# NAVSS0_VIRTSS_ECC_AGGR_0_VIRTSS_ECCAGGR_CFG register map
Vendor: Texas Instruments
Peripheral module from a debugger description file (folder J721S2).
Registers are 32-bit, access not given, reset 0x0 unless marked. A register's access mark holds for its fields unless they carry their own. Offsets are as the file gives them; lines under a group give offsets from that group; [hi:lo] are bit positions; {n}, {i} and the like mark numbered series; 'fields as' and 'values as' point back to an identical list; <NAME> marks a mode.

## NAVSS0_VIRTSS_ECC_AGGR_0_VIRTSS_ECCAGGR_CFG
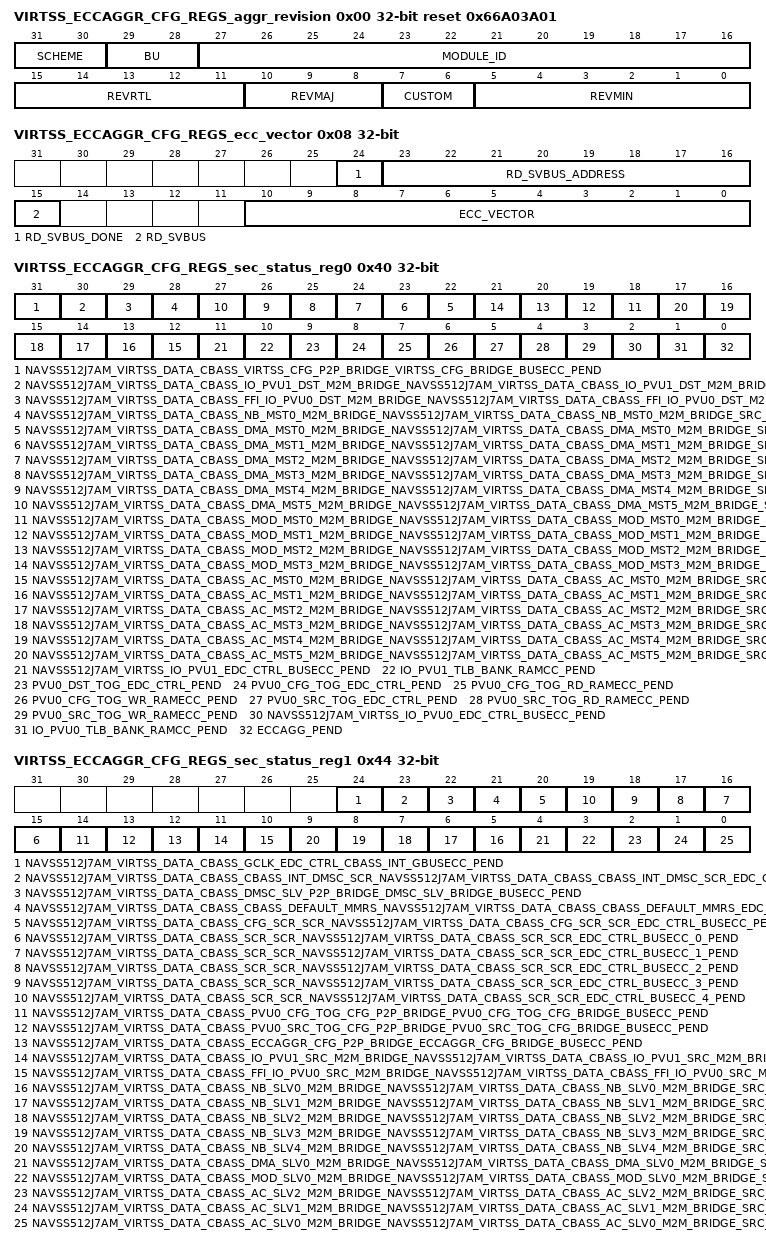
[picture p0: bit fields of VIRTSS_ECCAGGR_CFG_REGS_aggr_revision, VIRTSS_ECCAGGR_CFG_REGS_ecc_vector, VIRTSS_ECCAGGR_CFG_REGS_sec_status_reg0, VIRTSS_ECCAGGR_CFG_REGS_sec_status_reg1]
0x00 VIRTSS_ECCAGGR_CFG_REGS_aggr_revision ro reset 0x66A03A01 — Revision parameters
  [31:30] SCHEME
  [29:28] BU
  [27:16] MODULE_ID
  [15:11] REVRTL — RTL version
  [10:8] REVMAJ — Major version
  [7:6] CUSTOM — Custom version
  [5:0] REVMIN — Minor version
0x08 VIRTSS_ECCAGGR_CFG_REGS_ecc_vector — ECC Vector Register
  [24] RD_SVBUS_DONE — Status to indicate if read on serial VBUS is complete, write of any value will clear this bit. (access R/W1TC)
  [23:16] RD_SVBUS_ADDRESS rw — Read address
  [15] RD_SVBUS — Write 1 to trigger a read on the serial VBUS (access R/W1TS)
  [10:0] ECC_VECTOR rw — Value written to select the corresponding ECC RAM for control or status
0x0C VIRTSS_ECCAGGR_CFG_REGS_misc_status ro reset 0x39 — Misc Status
  [10:0] NUM_RAMS — Indicates the number of RAMS serviced by the ECC aggregator
0x10 VIRTSS_ECCAGGR_CFG_REGS_reserved_svbus rw — Reference other documents that contain the ECC RAM wrapper and EDC controller serial vbus register sets.
  [31:0] DATA — Serial VBUS register data
0x3C VIRTSS_ECCAGGR_CFG_REGS_sec_eoi_reg — EOI Register
  [0] EOI_WR — EOI Register (access R/W1TS)
0x40 VIRTSS_ECCAGGR_CFG_REGS_sec_status_reg0 — Interrupt Status Register 0
  [31] NAVSS512J7AM_VIRTSS_DATA_CBASS_VIRTSS_CFG_P2P_BRIDGE_VIRTSS_CFG_BRIDGE_BUSECC_PEND — Interrupt Pending Status for navss512j7am_virtss_data_cbass_virtss_cfg_p2p_bridge_virtss_cfg_bridge_busecc_pend (access R/W1TS)
  [30] NAVSS512J7AM_VIRTSS_DATA_CBASS_IO_PVU1_DST_M2M_BRIDGE_NAVSS512J7AM_VIRTSS_DATA_CBASS_IO_PVU1_DST_M2M_BRIDGE_SRC_EDC_CTRL_BUSECC_PEND — Interrupt Pending Status for navss512j7am_virtss_data_cbass_io_pvu1_dst_m2m_bridge_navss512j7am_virtss_data_cbass_io_pvu1_dst_m2m_bridge_src_edc_ctrl_busecc_pend (access R/W1TS)
  [29] NAVSS512J7AM_VIRTSS_DATA_CBASS_FFI_IO_PVU0_DST_M2M_BRIDGE_NAVSS512J7AM_VIRTSS_DATA_CBASS_FFI_IO_PVU0_DST_M2M_BRIDGE_SRC_EDC_CTRL_BUSECC_PEND — Interrupt Pending Status for navss512j7am_virtss_data_cbass_ffi_io_pvu0_dst_m2m_bridge_navss512j7am_virtss_data_cbass_ffi_io_pvu0_dst_m2m_bridge_src_edc_ctrl_busecc_pend (access R/W1TS)
  [28] NAVSS512J7AM_VIRTSS_DATA_CBASS_NB_MST0_M2M_BRIDGE_NAVSS512J7AM_VIRTSS_DATA_CBASS_NB_MST0_M2M_BRIDGE_SRC_EDC_CTRL_BUSECC_PEND — Interrupt Pending Status for navss512j7am_virtss_data_cbass_nb_mst0_m2m_bridge_navss512j7am_virtss_data_cbass_nb_mst0_m2m_bridge_src_edc_ctrl_busecc_pend (access R/W1TS)
  [n+22] NAVSS512J7AM_VIRTSS_DATA_CBASS_DMA_MST{n}_M2M_BRIDGE_NAVSS512J7AM_VIRTSS_DATA_CBASS_DMA_MST{n}_M2M_BRIDGE_SRC_EDC_CTRL_BUSECC_PEND (n=0..5) — Interrupt Pending Status for navss512j7am_virtss_data_cbass_dma_mst{n}_m2m_bridge_navss512j7am_virtss_data_cbass_dma_mst{n}_m2m_bridge_src_edc_ctrl_busecc_pend (access R/W1TS)
  [n+18] NAVSS512J7AM_VIRTSS_DATA_CBASS_MOD_MST{n}_M2M_BRIDGE_NAVSS512J7AM_VIRTSS_DATA_CBASS_MOD_MST{n}_M2M_BRIDGE_SRC_EDC_CTRL_BUSECC_PEND (n=0..3) — Interrupt Pending Status for navss512j7am_virtss_data_cbass_mod_mst{n}_m2m_bridge_navss512j7am_virtss_data_cbass_mod_mst{n}_m2m_bridge_src_edc_ctrl_busecc_pend (access R/W1TS)
  [n+12] NAVSS512J7AM_VIRTSS_DATA_CBASS_AC_MST{n}_M2M_BRIDGE_NAVSS512J7AM_VIRTSS_DATA_CBASS_AC_MST{n}_M2M_BRIDGE_SRC_EDC_CTRL_BUSECC_PEND (n=0..5) — Interrupt Pending Status for navss512j7am_virtss_data_cbass_ac_mst{n}_m2m_bridge_navss512j7am_virtss_data_cbass_ac_mst{n}_m2m_bridge_src_edc_ctrl_busecc_pend (access R/W1TS)
  [11] NAVSS512J7AM_VIRTSS_IO_PVU1_EDC_CTRL_BUSECC_PEND — Interrupt Pending Status for navss512j7am_virtss_io_pvu1_edc_ctrl_busecc_pend (access R/W1TS)
  [10] IO_PVU1_TLB_BANK_RAMCC_PEND — Interrupt Pending Status for io_pvu1_tlb_bank_ramcc_pend (access R/W1TS)
  [9] PVU0_DST_TOG_EDC_CTRL_PEND — Interrupt Pending Status for pvu0_dst_tog_edc_ctrl_pend (access R/W1TS)
  [8] PVU0_CFG_TOG_EDC_CTRL_PEND — Interrupt Pending Status for pvu0_cfg_tog_edc_ctrl_pend (access R/W1TS)
  [7] PVU0_CFG_TOG_RD_RAMECC_PEND — Interrupt Pending Status for pvu0_cfg_tog_rd_ramecc_pend (access R/W1TS)
  [6] PVU0_CFG_TOG_WR_RAMECC_PEND — Interrupt Pending Status for pvu0_cfg_tog_wr_ramecc_pend (access R/W1TS)
  [5] PVU0_SRC_TOG_EDC_CTRL_PEND — Interrupt Pending Status for pvu0_src_tog_edc_ctrl_pend (access R/W1TS)
  [4] PVU0_SRC_TOG_RD_RAMECC_PEND — Interrupt Pending Status for pvu0_src_tog_rd_ramecc_pend (access R/W1TS)
  [3] PVU0_SRC_TOG_WR_RAMECC_PEND — Interrupt Pending Status for pvu0_src_tog_wr_ramecc_pend (access R/W1TS)
  [2] NAVSS512J7AM_VIRTSS_IO_PVU0_EDC_CTRL_BUSECC_PEND — Interrupt Pending Status for navss512j7am_virtss_io_pvu0_edc_ctrl_busecc_pend (access R/W1TS)
  [1] IO_PVU0_TLB_BANK_RAMCC_PEND — Interrupt Pending Status for io_pvu0_tlb_bank_ramcc_pend (access R/W1TS)
  [0] ECCAGG_PEND — Interrupt Pending Status for eccagg_pend (access R/W1TS)
0x44 VIRTSS_ECCAGGR_CFG_REGS_sec_status_reg1 — Interrupt Status Register 1
  [24] NAVSS512J7AM_VIRTSS_DATA_CBASS_GCLK_EDC_CTRL_CBASS_INT_GBUSECC_PEND — Interrupt Pending Status for navss512j7am_virtss_data_cbass_gclk_edc_ctrl_cbass_int_gbusecc_pend (access R/W1TS)
  [23] NAVSS512J7AM_VIRTSS_DATA_CBASS_CBASS_INT_DMSC_SCR_NAVSS512J7AM_VIRTSS_DATA_CBASS_CBASS_INT_DMSC_SCR_EDC_CTRL_BUSECC_PEND — Interrupt Pending Status for navss512j7am_virtss_data_cbass_cbass_int_dmsc_scr_navss512j7am_virtss_data_cbass_cbass_int_dmsc_scr_edc_ctrl_busecc_pend (access R/W1TS)
  [22] NAVSS512J7AM_VIRTSS_DATA_CBASS_DMSC_SLV_P2P_BRIDGE_DMSC_SLV_BRIDGE_BUSECC_PEND — Interrupt Pending Status for navss512j7am_virtss_data_cbass_dmsc_slv_p2p_bridge_dmsc_slv_bridge_busecc_pend (access R/W1TS)
  [21] NAVSS512J7AM_VIRTSS_DATA_CBASS_CBASS_DEFAULT_MMRS_NAVSS512J7AM_VIRTSS_DATA_CBASS_CBASS_DEFAULT_MMRS_EDC_CTRL_BUSECC_PEND — Interrupt Pending Status for navss512j7am_virtss_data_cbass_cbass_default_mmrs_navss512j7am_virtss_data_cbass_cbass_default_mmrs_edc_ctrl_busecc_pend (access R/W1TS)
  [20] NAVSS512J7AM_VIRTSS_DATA_CBASS_CFG_SCR_SCR_NAVSS512J7AM_VIRTSS_DATA_CBASS_CFG_SCR_SCR_EDC_CTRL_BUSECC_PEND — Interrupt Pending Status for navss512j7am_virtss_data_cbass_cfg_scr_scr_navss512j7am_virtss_data_cbass_cfg_scr_scr_edc_ctrl_busecc_pend (access R/W1TS)
  [n+15] NAVSS512J7AM_VIRTSS_DATA_CBASS_SCR_SCR_NAVSS512J7AM_VIRTSS_DATA_CBASS_SCR_SCR_EDC_CTRL_BUSECC_{n}_PEND (n=0..4) — Interrupt Pending Status for navss512j7am_virtss_data_cbass_scr_scr_navss512j7am_virtss_data_cbass_scr_scr_edc_ctrl_busecc_{n}_pend (access R/W1TS)
  [14] NAVSS512J7AM_VIRTSS_DATA_CBASS_PVU0_CFG_TOG_CFG_P2P_BRIDGE_PVU0_CFG_TOG_CFG_BRIDGE_BUSECC_PEND — Interrupt Pending Status for navss512j7am_virtss_data_cbass_pvu0_cfg_tog_cfg_p2p_bridge_pvu0_cfg_tog_cfg_bridge_busecc_pend (access R/W1TS)
  [13] NAVSS512J7AM_VIRTSS_DATA_CBASS_PVU0_SRC_TOG_CFG_P2P_BRIDGE_PVU0_SRC_TOG_CFG_BRIDGE_BUSECC_PEND — Interrupt Pending Status for navss512j7am_virtss_data_cbass_pvu0_src_tog_cfg_p2p_bridge_pvu0_src_tog_cfg_bridge_busecc_pend (access R/W1TS)
  [12] NAVSS512J7AM_VIRTSS_DATA_CBASS_ECCAGGR_CFG_P2P_BRIDGE_ECCAGGR_CFG_BRIDGE_BUSECC_PEND — Interrupt Pending Status for navss512j7am_virtss_data_cbass_eccaggr_cfg_p2p_bridge_eccaggr_cfg_bridge_busecc_pend (access R/W1TS)
  [11] NAVSS512J7AM_VIRTSS_DATA_CBASS_IO_PVU1_SRC_M2M_BRIDGE_NAVSS512J7AM_VIRTSS_DATA_CBASS_IO_PVU1_SRC_M2M_BRIDGE_SRC_EDC_CTRL_BUSECC_PEND — Interrupt Pending Status for navss512j7am_virtss_data_cbass_io_pvu1_src_m2m_bridge_navss512j7am_virtss_data_cbass_io_pvu1_src_m2m_bridge_src_edc_ctrl_busecc_pend (access R/W1TS)
  [10] NAVSS512J7AM_VIRTSS_DATA_CBASS_FFI_IO_PVU0_SRC_M2M_BRIDGE_NAVSS512J7AM_VIRTSS_DATA_CBASS_FFI_IO_PVU0_SRC_M2M_BRIDGE_SRC_EDC_CTRL_BUSECC_PEND — Interrupt Pending Status for navss512j7am_virtss_data_cbass_ffi_io_pvu0_src_m2m_bridge_navss512j7am_virtss_data_cbass_ffi_io_pvu0_src_m2m_bridge_src_edc_ctrl_busecc_pend (access R/W1TS)
  [n+5] NAVSS512J7AM_VIRTSS_DATA_CBASS_NB_SLV{n}_M2M_BRIDGE_NAVSS512J7AM_VIRTSS_DATA_CBASS_NB_SLV{n}_M2M_BRIDGE_SRC_EDC_CTRL_BUSECC_PEND (n=0..4) — Interrupt Pending Status for navss512j7am_virtss_data_cbass_nb_slv{n}_m2m_bridge_navss512j7am_virtss_data_cbass_nb_slv{n}_m2m_bridge_src_edc_ctrl_busecc_pend (access R/W1TS)
  [4] NAVSS512J7AM_VIRTSS_DATA_CBASS_DMA_SLV0_M2M_BRIDGE_NAVSS512J7AM_VIRTSS_DATA_CBASS_DMA_SLV0_M2M_BRIDGE_SRC_EDC_CTRL_BUSECC_PEND — Interrupt Pending Status for navss512j7am_virtss_data_cbass_dma_slv0_m2m_bridge_navss512j7am_virtss_data_cbass_dma_slv0_m2m_bridge_src_edc_ctrl_busecc_pend (access R/W1TS)
  [3] NAVSS512J7AM_VIRTSS_DATA_CBASS_MOD_SLV0_M2M_BRIDGE_NAVSS512J7AM_VIRTSS_DATA_CBASS_MOD_SLV0_M2M_BRIDGE_SRC_EDC_CTRL_BUSECC_PEND — Interrupt Pending Status for navss512j7am_virtss_data_cbass_mod_slv0_m2m_bridge_navss512j7am_virtss_data_cbass_mod_slv0_m2m_bridge_src_edc_ctrl_busecc_pend (access R/W1TS)
  [2] NAVSS512J7AM_VIRTSS_DATA_CBASS_AC_SLV2_M2M_BRIDGE_NAVSS512J7AM_VIRTSS_DATA_CBASS_AC_SLV2_M2M_BRIDGE_SRC_EDC_CTRL_BUSECC_PEND — Interrupt Pending Status for navss512j7am_virtss_data_cbass_ac_slv2_m2m_bridge_navss512j7am_virtss_data_cbass_ac_slv2_m2m_bridge_src_edc_ctrl_busecc_pend (access R/W1TS)
  [1] NAVSS512J7AM_VIRTSS_DATA_CBASS_AC_SLV1_M2M_BRIDGE_NAVSS512J7AM_VIRTSS_DATA_CBASS_AC_SLV1_M2M_BRIDGE_SRC_EDC_CTRL_BUSECC_PEND — Interrupt Pending Status for navss512j7am_virtss_data_cbass_ac_slv1_m2m_bridge_navss512j7am_virtss_data_cbass_ac_slv1_m2m_bridge_src_edc_ctrl_busecc_pend (access R/W1TS)
  [0] NAVSS512J7AM_VIRTSS_DATA_CBASS_AC_SLV0_M2M_BRIDGE_NAVSS512J7AM_VIRTSS_DATA_CBASS_AC_SLV0_M2M_BRIDGE_SRC_EDC_CTRL_BUSECC_PEND — Interrupt Pending Status for navss512j7am_virtss_data_cbass_ac_slv0_m2m_bridge_navss512j7am_virtss_data_cbass_ac_slv0_m2m_bridge_src_edc_ctrl_busecc_pend (access R/W1TS)
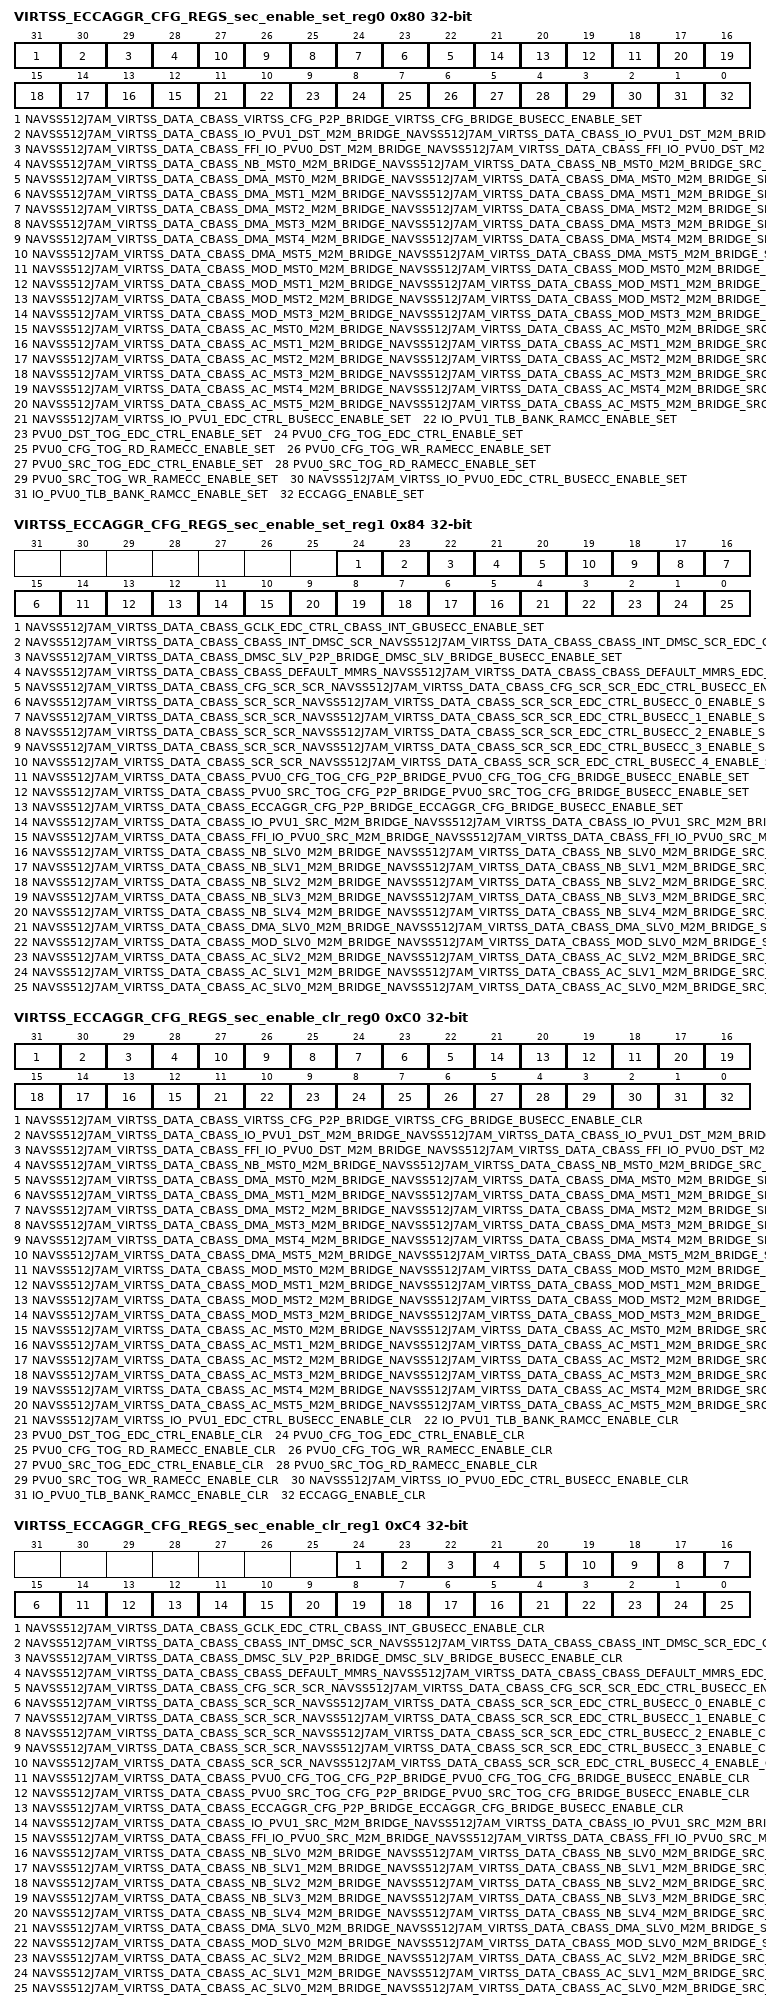
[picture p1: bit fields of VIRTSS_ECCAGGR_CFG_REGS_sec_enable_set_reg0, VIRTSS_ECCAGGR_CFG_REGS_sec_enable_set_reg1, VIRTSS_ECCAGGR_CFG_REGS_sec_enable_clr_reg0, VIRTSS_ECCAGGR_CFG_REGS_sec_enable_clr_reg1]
0x80 VIRTSS_ECCAGGR_CFG_REGS_sec_enable_set_reg0 — Interrupt Enable Set Register 0
  [31] NAVSS512J7AM_VIRTSS_DATA_CBASS_VIRTSS_CFG_P2P_BRIDGE_VIRTSS_CFG_BRIDGE_BUSECC_ENABLE_SET — Interrupt Enable Set Register for navss512j7am_virtss_data_cbass_virtss_cfg_p2p_bridge_virtss_cfg_bridge_busecc_pend (access R/W1TS)
  [30] NAVSS512J7AM_VIRTSS_DATA_CBASS_IO_PVU1_DST_M2M_BRIDGE_NAVSS512J7AM_VIRTSS_DATA_CBASS_IO_PVU1_DST_M2M_BRIDGE_SRC_EDC_CTRL_BUSECC_ENABLE_SET — Interrupt Enable Set Register for navss512j7am_virtss_data_cbass_io_pvu1_dst_m2m_bridge_navss512j7am_virtss_data_cbass_io_pvu1_dst_m2m_bridge_src_edc_ctrl_busecc_pend (access R/W1TS)
  [29] NAVSS512J7AM_VIRTSS_DATA_CBASS_FFI_IO_PVU0_DST_M2M_BRIDGE_NAVSS512J7AM_VIRTSS_DATA_CBASS_FFI_IO_PVU0_DST_M2M_BRIDGE_SRC_EDC_CTRL_BUSECC_ENABLE_SET — Interrupt Enable Set Register for navss512j7am_virtss_data_cbass_ffi_io_pvu0_dst_m2m_bridge_navss512j7am_virtss_data_cbass_ffi_io_pvu0_dst_m2m_bridge_src_edc_ctrl_busecc_pend (access R/W1TS)
  [28] NAVSS512J7AM_VIRTSS_DATA_CBASS_NB_MST0_M2M_BRIDGE_NAVSS512J7AM_VIRTSS_DATA_CBASS_NB_MST0_M2M_BRIDGE_SRC_EDC_CTRL_BUSECC_ENABLE_SET — Interrupt Enable Set Register for navss512j7am_virtss_data_cbass_nb_mst0_m2m_bridge_navss512j7am_virtss_data_cbass_nb_mst0_m2m_bridge_src_edc_ctrl_busecc_pend (access R/W1TS)
  [n+22] NAVSS512J7AM_VIRTSS_DATA_CBASS_DMA_MST{n}_M2M_BRIDGE_NAVSS512J7AM_VIRTSS_DATA_CBASS_DMA_MST{n}_M2M_BRIDGE_SRC_EDC_CTRL_BUSECC_ENABLE_SET (n=0..5) — Interrupt Enable Set Register for navss512j7am_virtss_data_cbass_dma_mst{n}_m2m_bridge_navss512j7am_virtss_data_cbass_dma_mst{n}_m2m_bridge_src_edc_ctrl_busecc_pend (access R/W1TS)
  [n+18] NAVSS512J7AM_VIRTSS_DATA_CBASS_MOD_MST{n}_M2M_BRIDGE_NAVSS512J7AM_VIRTSS_DATA_CBASS_MOD_MST{n}_M2M_BRIDGE_SRC_EDC_CTRL_BUSECC_ENABLE_SET (n=0..3) — Interrupt Enable Set Register for navss512j7am_virtss_data_cbass_mod_mst{n}_m2m_bridge_navss512j7am_virtss_data_cbass_mod_mst{n}_m2m_bridge_src_edc_ctrl_busecc_pend (access R/W1TS)
  [n+12] NAVSS512J7AM_VIRTSS_DATA_CBASS_AC_MST{n}_M2M_BRIDGE_NAVSS512J7AM_VIRTSS_DATA_CBASS_AC_MST{n}_M2M_BRIDGE_SRC_EDC_CTRL_BUSECC_ENABLE_SET (n=0..5) — Interrupt Enable Set Register for navss512j7am_virtss_data_cbass_ac_mst{n}_m2m_bridge_navss512j7am_virtss_data_cbass_ac_mst{n}_m2m_bridge_src_edc_ctrl_busecc_pend (access R/W1TS)
  [11] NAVSS512J7AM_VIRTSS_IO_PVU1_EDC_CTRL_BUSECC_ENABLE_SET — Interrupt Enable Set Register for navss512j7am_virtss_io_pvu1_edc_ctrl_busecc_pend (access R/W1TS)
  [10] IO_PVU1_TLB_BANK_RAMCC_ENABLE_SET — Interrupt Enable Set Register for io_pvu1_tlb_bank_ramcc_pend (access R/W1TS)
  [9] PVU0_DST_TOG_EDC_CTRL_ENABLE_SET — Interrupt Enable Set Register for pvu0_dst_tog_edc_ctrl_pend (access R/W1TS)
  [8] PVU0_CFG_TOG_EDC_CTRL_ENABLE_SET — Interrupt Enable Set Register for pvu0_cfg_tog_edc_ctrl_pend (access R/W1TS)
  [7] PVU0_CFG_TOG_RD_RAMECC_ENABLE_SET — Interrupt Enable Set Register for pvu0_cfg_tog_rd_ramecc_pend (access R/W1TS)
  [6] PVU0_CFG_TOG_WR_RAMECC_ENABLE_SET — Interrupt Enable Set Register for pvu0_cfg_tog_wr_ramecc_pend (access R/W1TS)
  [5] PVU0_SRC_TOG_EDC_CTRL_ENABLE_SET — Interrupt Enable Set Register for pvu0_src_tog_edc_ctrl_pend (access R/W1TS)
  [4] PVU0_SRC_TOG_RD_RAMECC_ENABLE_SET — Interrupt Enable Set Register for pvu0_src_tog_rd_ramecc_pend (access R/W1TS)
  [3] PVU0_SRC_TOG_WR_RAMECC_ENABLE_SET — Interrupt Enable Set Register for pvu0_src_tog_wr_ramecc_pend (access R/W1TS)
  [2] NAVSS512J7AM_VIRTSS_IO_PVU0_EDC_CTRL_BUSECC_ENABLE_SET — Interrupt Enable Set Register for navss512j7am_virtss_io_pvu0_edc_ctrl_busecc_pend (access R/W1TS)
  [1] IO_PVU0_TLB_BANK_RAMCC_ENABLE_SET — Interrupt Enable Set Register for io_pvu0_tlb_bank_ramcc_pend (access R/W1TS)
  [0] ECCAGG_ENABLE_SET — Interrupt Enable Set Register for eccagg_pend (access R/W1TS)
0x84 VIRTSS_ECCAGGR_CFG_REGS_sec_enable_set_reg1 — Interrupt Enable Set Register 1
  [24] NAVSS512J7AM_VIRTSS_DATA_CBASS_GCLK_EDC_CTRL_CBASS_INT_GBUSECC_ENABLE_SET — Interrupt Enable Set Register for navss512j7am_virtss_data_cbass_gclk_edc_ctrl_cbass_int_gbusecc_pend (access R/W1TS)
  [23] NAVSS512J7AM_VIRTSS_DATA_CBASS_CBASS_INT_DMSC_SCR_NAVSS512J7AM_VIRTSS_DATA_CBASS_CBASS_INT_DMSC_SCR_EDC_CTRL_BUSECC_ENABLE_SET — Interrupt Enable Set Register for navss512j7am_virtss_data_cbass_cbass_int_dmsc_scr_navss512j7am_virtss_data_cbass_cbass_int_dmsc_scr_edc_ctrl_busecc_pend (access R/W1TS)
  [22] NAVSS512J7AM_VIRTSS_DATA_CBASS_DMSC_SLV_P2P_BRIDGE_DMSC_SLV_BRIDGE_BUSECC_ENABLE_SET — Interrupt Enable Set Register for navss512j7am_virtss_data_cbass_dmsc_slv_p2p_bridge_dmsc_slv_bridge_busecc_pend (access R/W1TS)
  [21] NAVSS512J7AM_VIRTSS_DATA_CBASS_CBASS_DEFAULT_MMRS_NAVSS512J7AM_VIRTSS_DATA_CBASS_CBASS_DEFAULT_MMRS_EDC_CTRL_BUSECC_ENABLE_SET — Interrupt Enable Set Register for navss512j7am_virtss_data_cbass_cbass_default_mmrs_navss512j7am_virtss_data_cbass_cbass_default_mmrs_edc_ctrl_busecc_pend (access R/W1TS)
  [20] NAVSS512J7AM_VIRTSS_DATA_CBASS_CFG_SCR_SCR_NAVSS512J7AM_VIRTSS_DATA_CBASS_CFG_SCR_SCR_EDC_CTRL_BUSECC_ENABLE_SET — Interrupt Enable Set Register for navss512j7am_virtss_data_cbass_cfg_scr_scr_navss512j7am_virtss_data_cbass_cfg_scr_scr_edc_ctrl_busecc_pend (access R/W1TS)
  [n+15] NAVSS512J7AM_VIRTSS_DATA_CBASS_SCR_SCR_NAVSS512J7AM_VIRTSS_DATA_CBASS_SCR_SCR_EDC_CTRL_BUSECC_{n}_ENABLE_SET (n=0..4) — Interrupt Enable Set Register for navss512j7am_virtss_data_cbass_scr_scr_navss512j7am_virtss_data_cbass_scr_scr_edc_ctrl_busecc_{n}_pend (access R/W1TS)
  [14] NAVSS512J7AM_VIRTSS_DATA_CBASS_PVU0_CFG_TOG_CFG_P2P_BRIDGE_PVU0_CFG_TOG_CFG_BRIDGE_BUSECC_ENABLE_SET — Interrupt Enable Set Register for navss512j7am_virtss_data_cbass_pvu0_cfg_tog_cfg_p2p_bridge_pvu0_cfg_tog_cfg_bridge_busecc_pend (access R/W1TS)
  [13] NAVSS512J7AM_VIRTSS_DATA_CBASS_PVU0_SRC_TOG_CFG_P2P_BRIDGE_PVU0_SRC_TOG_CFG_BRIDGE_BUSECC_ENABLE_SET — Interrupt Enable Set Register for navss512j7am_virtss_data_cbass_pvu0_src_tog_cfg_p2p_bridge_pvu0_src_tog_cfg_bridge_busecc_pend (access R/W1TS)
  [12] NAVSS512J7AM_VIRTSS_DATA_CBASS_ECCAGGR_CFG_P2P_BRIDGE_ECCAGGR_CFG_BRIDGE_BUSECC_ENABLE_SET — Interrupt Enable Set Register for navss512j7am_virtss_data_cbass_eccaggr_cfg_p2p_bridge_eccaggr_cfg_bridge_busecc_pend (access R/W1TS)
  [11] NAVSS512J7AM_VIRTSS_DATA_CBASS_IO_PVU1_SRC_M2M_BRIDGE_NAVSS512J7AM_VIRTSS_DATA_CBASS_IO_PVU1_SRC_M2M_BRIDGE_SRC_EDC_CTRL_BUSECC_ENABLE_SET — Interrupt Enable Set Register for navss512j7am_virtss_data_cbass_io_pvu1_src_m2m_bridge_navss512j7am_virtss_data_cbass_io_pvu1_src_m2m_bridge_src_edc_ctrl_busecc_pend (access R/W1TS)
  [10] NAVSS512J7AM_VIRTSS_DATA_CBASS_FFI_IO_PVU0_SRC_M2M_BRIDGE_NAVSS512J7AM_VIRTSS_DATA_CBASS_FFI_IO_PVU0_SRC_M2M_BRIDGE_SRC_EDC_CTRL_BUSECC_ENABLE_SET — Interrupt Enable Set Register for navss512j7am_virtss_data_cbass_ffi_io_pvu0_src_m2m_bridge_navss512j7am_virtss_data_cbass_ffi_io_pvu0_src_m2m_bridge_src_edc_ctrl_busecc_pend (access R/W1TS)
  [n+5] NAVSS512J7AM_VIRTSS_DATA_CBASS_NB_SLV{n}_M2M_BRIDGE_NAVSS512J7AM_VIRTSS_DATA_CBASS_NB_SLV{n}_M2M_BRIDGE_SRC_EDC_CTRL_BUSECC_ENABLE_SET (n=0..4) — Interrupt Enable Set Register for navss512j7am_virtss_data_cbass_nb_slv{n}_m2m_bridge_navss512j7am_virtss_data_cbass_nb_slv{n}_m2m_bridge_src_edc_ctrl_busecc_pend (access R/W1TS)
  [4] NAVSS512J7AM_VIRTSS_DATA_CBASS_DMA_SLV0_M2M_BRIDGE_NAVSS512J7AM_VIRTSS_DATA_CBASS_DMA_SLV0_M2M_BRIDGE_SRC_EDC_CTRL_BUSECC_ENABLE_SET — Interrupt Enable Set Register for navss512j7am_virtss_data_cbass_dma_slv0_m2m_bridge_navss512j7am_virtss_data_cbass_dma_slv0_m2m_bridge_src_edc_ctrl_busecc_pend (access R/W1TS)
  [3] NAVSS512J7AM_VIRTSS_DATA_CBASS_MOD_SLV0_M2M_BRIDGE_NAVSS512J7AM_VIRTSS_DATA_CBASS_MOD_SLV0_M2M_BRIDGE_SRC_EDC_CTRL_BUSECC_ENABLE_SET — Interrupt Enable Set Register for navss512j7am_virtss_data_cbass_mod_slv0_m2m_bridge_navss512j7am_virtss_data_cbass_mod_slv0_m2m_bridge_src_edc_ctrl_busecc_pend (access R/W1TS)
  [2] NAVSS512J7AM_VIRTSS_DATA_CBASS_AC_SLV2_M2M_BRIDGE_NAVSS512J7AM_VIRTSS_DATA_CBASS_AC_SLV2_M2M_BRIDGE_SRC_EDC_CTRL_BUSECC_ENABLE_SET — Interrupt Enable Set Register for navss512j7am_virtss_data_cbass_ac_slv2_m2m_bridge_navss512j7am_virtss_data_cbass_ac_slv2_m2m_bridge_src_edc_ctrl_busecc_pend (access R/W1TS)
  [1] NAVSS512J7AM_VIRTSS_DATA_CBASS_AC_SLV1_M2M_BRIDGE_NAVSS512J7AM_VIRTSS_DATA_CBASS_AC_SLV1_M2M_BRIDGE_SRC_EDC_CTRL_BUSECC_ENABLE_SET — Interrupt Enable Set Register for navss512j7am_virtss_data_cbass_ac_slv1_m2m_bridge_navss512j7am_virtss_data_cbass_ac_slv1_m2m_bridge_src_edc_ctrl_busecc_pend (access R/W1TS)
  [0] NAVSS512J7AM_VIRTSS_DATA_CBASS_AC_SLV0_M2M_BRIDGE_NAVSS512J7AM_VIRTSS_DATA_CBASS_AC_SLV0_M2M_BRIDGE_SRC_EDC_CTRL_BUSECC_ENABLE_SET — Interrupt Enable Set Register for navss512j7am_virtss_data_cbass_ac_slv0_m2m_bridge_navss512j7am_virtss_data_cbass_ac_slv0_m2m_bridge_src_edc_ctrl_busecc_pend (access R/W1TS)
0xC0 VIRTSS_ECCAGGR_CFG_REGS_sec_enable_clr_reg0 — Interrupt Enable Clear Register 0
  [31] NAVSS512J7AM_VIRTSS_DATA_CBASS_VIRTSS_CFG_P2P_BRIDGE_VIRTSS_CFG_BRIDGE_BUSECC_ENABLE_CLR — Interrupt Enable Clear Register for navss512j7am_virtss_data_cbass_virtss_cfg_p2p_bridge_virtss_cfg_bridge_busecc_pend (access R/W1TC)
  [30] NAVSS512J7AM_VIRTSS_DATA_CBASS_IO_PVU1_DST_M2M_BRIDGE_NAVSS512J7AM_VIRTSS_DATA_CBASS_IO_PVU1_DST_M2M_BRIDGE_SRC_EDC_CTRL_BUSECC_ENABLE_CLR — Interrupt Enable Clear Register for navss512j7am_virtss_data_cbass_io_pvu1_dst_m2m_bridge_navss512j7am_virtss_data_cbass_io_pvu1_dst_m2m_bridge_src_edc_ctrl_busecc_pend (access R/W1TC)
  [29] NAVSS512J7AM_VIRTSS_DATA_CBASS_FFI_IO_PVU0_DST_M2M_BRIDGE_NAVSS512J7AM_VIRTSS_DATA_CBASS_FFI_IO_PVU0_DST_M2M_BRIDGE_SRC_EDC_CTRL_BUSECC_ENABLE_CLR — Interrupt Enable Clear Register for navss512j7am_virtss_data_cbass_ffi_io_pvu0_dst_m2m_bridge_navss512j7am_virtss_data_cbass_ffi_io_pvu0_dst_m2m_bridge_src_edc_ctrl_busecc_pend (access R/W1TC)
  [28] NAVSS512J7AM_VIRTSS_DATA_CBASS_NB_MST0_M2M_BRIDGE_NAVSS512J7AM_VIRTSS_DATA_CBASS_NB_MST0_M2M_BRIDGE_SRC_EDC_CTRL_BUSECC_ENABLE_CLR — Interrupt Enable Clear Register for navss512j7am_virtss_data_cbass_nb_mst0_m2m_bridge_navss512j7am_virtss_data_cbass_nb_mst0_m2m_bridge_src_edc_ctrl_busecc_pend (access R/W1TC)
  [n+22] NAVSS512J7AM_VIRTSS_DATA_CBASS_DMA_MST{n}_M2M_BRIDGE_NAVSS512J7AM_VIRTSS_DATA_CBASS_DMA_MST{n}_M2M_BRIDGE_SRC_EDC_CTRL_BUSECC_ENABLE_CLR (n=0..5) — Interrupt Enable Clear Register for navss512j7am_virtss_data_cbass_dma_mst{n}_m2m_bridge_navss512j7am_virtss_data_cbass_dma_mst{n}_m2m_bridge_src_edc_ctrl_busecc_pend (access R/W1TC)
  [n+18] NAVSS512J7AM_VIRTSS_DATA_CBASS_MOD_MST{n}_M2M_BRIDGE_NAVSS512J7AM_VIRTSS_DATA_CBASS_MOD_MST{n}_M2M_BRIDGE_SRC_EDC_CTRL_BUSECC_ENABLE_CLR (n=0..3) — Interrupt Enable Clear Register for navss512j7am_virtss_data_cbass_mod_mst{n}_m2m_bridge_navss512j7am_virtss_data_cbass_mod_mst{n}_m2m_bridge_src_edc_ctrl_busecc_pend (access R/W1TC)
  [n+12] NAVSS512J7AM_VIRTSS_DATA_CBASS_AC_MST{n}_M2M_BRIDGE_NAVSS512J7AM_VIRTSS_DATA_CBASS_AC_MST{n}_M2M_BRIDGE_SRC_EDC_CTRL_BUSECC_ENABLE_CLR (n=0..5) — Interrupt Enable Clear Register for navss512j7am_virtss_data_cbass_ac_mst{n}_m2m_bridge_navss512j7am_virtss_data_cbass_ac_mst{n}_m2m_bridge_src_edc_ctrl_busecc_pend (access R/W1TC)
  [11] NAVSS512J7AM_VIRTSS_IO_PVU1_EDC_CTRL_BUSECC_ENABLE_CLR — Interrupt Enable Clear Register for navss512j7am_virtss_io_pvu1_edc_ctrl_busecc_pend (access R/W1TC)
  [10] IO_PVU1_TLB_BANK_RAMCC_ENABLE_CLR — Interrupt Enable Clear Register for io_pvu1_tlb_bank_ramcc_pend (access R/W1TC)
  [9] PVU0_DST_TOG_EDC_CTRL_ENABLE_CLR — Interrupt Enable Clear Register for pvu0_dst_tog_edc_ctrl_pend (access R/W1TC)
  [8] PVU0_CFG_TOG_EDC_CTRL_ENABLE_CLR — Interrupt Enable Clear Register for pvu0_cfg_tog_edc_ctrl_pend (access R/W1TC)
  [7] PVU0_CFG_TOG_RD_RAMECC_ENABLE_CLR — Interrupt Enable Clear Register for pvu0_cfg_tog_rd_ramecc_pend (access R/W1TC)
  [6] PVU0_CFG_TOG_WR_RAMECC_ENABLE_CLR — Interrupt Enable Clear Register for pvu0_cfg_tog_wr_ramecc_pend (access R/W1TC)
  [5] PVU0_SRC_TOG_EDC_CTRL_ENABLE_CLR — Interrupt Enable Clear Register for pvu0_src_tog_edc_ctrl_pend (access R/W1TC)
  [4] PVU0_SRC_TOG_RD_RAMECC_ENABLE_CLR — Interrupt Enable Clear Register for pvu0_src_tog_rd_ramecc_pend (access R/W1TC)
  [3] PVU0_SRC_TOG_WR_RAMECC_ENABLE_CLR — Interrupt Enable Clear Register for pvu0_src_tog_wr_ramecc_pend (access R/W1TC)
  [2] NAVSS512J7AM_VIRTSS_IO_PVU0_EDC_CTRL_BUSECC_ENABLE_CLR — Interrupt Enable Clear Register for navss512j7am_virtss_io_pvu0_edc_ctrl_busecc_pend (access R/W1TC)
  [1] IO_PVU0_TLB_BANK_RAMCC_ENABLE_CLR — Interrupt Enable Clear Register for io_pvu0_tlb_bank_ramcc_pend (access R/W1TC)
  [0] ECCAGG_ENABLE_CLR — Interrupt Enable Clear Register for eccagg_pend (access R/W1TC)
0xC4 VIRTSS_ECCAGGR_CFG_REGS_sec_enable_clr_reg1 — Interrupt Enable Clear Register 1
  [24] NAVSS512J7AM_VIRTSS_DATA_CBASS_GCLK_EDC_CTRL_CBASS_INT_GBUSECC_ENABLE_CLR — Interrupt Enable Clear Register for navss512j7am_virtss_data_cbass_gclk_edc_ctrl_cbass_int_gbusecc_pend (access R/W1TC)
  [23] NAVSS512J7AM_VIRTSS_DATA_CBASS_CBASS_INT_DMSC_SCR_NAVSS512J7AM_VIRTSS_DATA_CBASS_CBASS_INT_DMSC_SCR_EDC_CTRL_BUSECC_ENABLE_CLR — Interrupt Enable Clear Register for navss512j7am_virtss_data_cbass_cbass_int_dmsc_scr_navss512j7am_virtss_data_cbass_cbass_int_dmsc_scr_edc_ctrl_busecc_pend (access R/W1TC)
  [22] NAVSS512J7AM_VIRTSS_DATA_CBASS_DMSC_SLV_P2P_BRIDGE_DMSC_SLV_BRIDGE_BUSECC_ENABLE_CLR — Interrupt Enable Clear Register for navss512j7am_virtss_data_cbass_dmsc_slv_p2p_bridge_dmsc_slv_bridge_busecc_pend (access R/W1TC)
  [21] NAVSS512J7AM_VIRTSS_DATA_CBASS_CBASS_DEFAULT_MMRS_NAVSS512J7AM_VIRTSS_DATA_CBASS_CBASS_DEFAULT_MMRS_EDC_CTRL_BUSECC_ENABLE_CLR — Interrupt Enable Clear Register for navss512j7am_virtss_data_cbass_cbass_default_mmrs_navss512j7am_virtss_data_cbass_cbass_default_mmrs_edc_ctrl_busecc_pend (access R/W1TC)
  [20] NAVSS512J7AM_VIRTSS_DATA_CBASS_CFG_SCR_SCR_NAVSS512J7AM_VIRTSS_DATA_CBASS_CFG_SCR_SCR_EDC_CTRL_BUSECC_ENABLE_CLR — Interrupt Enable Clear Register for navss512j7am_virtss_data_cbass_cfg_scr_scr_navss512j7am_virtss_data_cbass_cfg_scr_scr_edc_ctrl_busecc_pend (access R/W1TC)
  [n+15] NAVSS512J7AM_VIRTSS_DATA_CBASS_SCR_SCR_NAVSS512J7AM_VIRTSS_DATA_CBASS_SCR_SCR_EDC_CTRL_BUSECC_{n}_ENABLE_CLR (n=0..4) — Interrupt Enable Clear Register for navss512j7am_virtss_data_cbass_scr_scr_navss512j7am_virtss_data_cbass_scr_scr_edc_ctrl_busecc_{n}_pend (access R/W1TC)
  [14] NAVSS512J7AM_VIRTSS_DATA_CBASS_PVU0_CFG_TOG_CFG_P2P_BRIDGE_PVU0_CFG_TOG_CFG_BRIDGE_BUSECC_ENABLE_CLR — Interrupt Enable Clear Register for navss512j7am_virtss_data_cbass_pvu0_cfg_tog_cfg_p2p_bridge_pvu0_cfg_tog_cfg_bridge_busecc_pend (access R/W1TC)
  [13] NAVSS512J7AM_VIRTSS_DATA_CBASS_PVU0_SRC_TOG_CFG_P2P_BRIDGE_PVU0_SRC_TOG_CFG_BRIDGE_BUSECC_ENABLE_CLR — Interrupt Enable Clear Register for navss512j7am_virtss_data_cbass_pvu0_src_tog_cfg_p2p_bridge_pvu0_src_tog_cfg_bridge_busecc_pend (access R/W1TC)
  [12] NAVSS512J7AM_VIRTSS_DATA_CBASS_ECCAGGR_CFG_P2P_BRIDGE_ECCAGGR_CFG_BRIDGE_BUSECC_ENABLE_CLR — Interrupt Enable Clear Register for navss512j7am_virtss_data_cbass_eccaggr_cfg_p2p_bridge_eccaggr_cfg_bridge_busecc_pend (access R/W1TC)
  [11] NAVSS512J7AM_VIRTSS_DATA_CBASS_IO_PVU1_SRC_M2M_BRIDGE_NAVSS512J7AM_VIRTSS_DATA_CBASS_IO_PVU1_SRC_M2M_BRIDGE_SRC_EDC_CTRL_BUSECC_ENABLE_CLR — Interrupt Enable Clear Register for navss512j7am_virtss_data_cbass_io_pvu1_src_m2m_bridge_navss512j7am_virtss_data_cbass_io_pvu1_src_m2m_bridge_src_edc_ctrl_busecc_pend (access R/W1TC)
  [10] NAVSS512J7AM_VIRTSS_DATA_CBASS_FFI_IO_PVU0_SRC_M2M_BRIDGE_NAVSS512J7AM_VIRTSS_DATA_CBASS_FFI_IO_PVU0_SRC_M2M_BRIDGE_SRC_EDC_CTRL_BUSECC_ENABLE_CLR — Interrupt Enable Clear Register for navss512j7am_virtss_data_cbass_ffi_io_pvu0_src_m2m_bridge_navss512j7am_virtss_data_cbass_ffi_io_pvu0_src_m2m_bridge_src_edc_ctrl_busecc_pend (access R/W1TC)
  [n+5] NAVSS512J7AM_VIRTSS_DATA_CBASS_NB_SLV{n}_M2M_BRIDGE_NAVSS512J7AM_VIRTSS_DATA_CBASS_NB_SLV{n}_M2M_BRIDGE_SRC_EDC_CTRL_BUSECC_ENABLE_CLR (n=0..4) — Interrupt Enable Clear Register for navss512j7am_virtss_data_cbass_nb_slv{n}_m2m_bridge_navss512j7am_virtss_data_cbass_nb_slv{n}_m2m_bridge_src_edc_ctrl_busecc_pend (access R/W1TC)
  [4] NAVSS512J7AM_VIRTSS_DATA_CBASS_DMA_SLV0_M2M_BRIDGE_NAVSS512J7AM_VIRTSS_DATA_CBASS_DMA_SLV0_M2M_BRIDGE_SRC_EDC_CTRL_BUSECC_ENABLE_CLR — Interrupt Enable Clear Register for navss512j7am_virtss_data_cbass_dma_slv0_m2m_bridge_navss512j7am_virtss_data_cbass_dma_slv0_m2m_bridge_src_edc_ctrl_busecc_pend (access R/W1TC)
  [3] NAVSS512J7AM_VIRTSS_DATA_CBASS_MOD_SLV0_M2M_BRIDGE_NAVSS512J7AM_VIRTSS_DATA_CBASS_MOD_SLV0_M2M_BRIDGE_SRC_EDC_CTRL_BUSECC_ENABLE_CLR — Interrupt Enable Clear Register for navss512j7am_virtss_data_cbass_mod_slv0_m2m_bridge_navss512j7am_virtss_data_cbass_mod_slv0_m2m_bridge_src_edc_ctrl_busecc_pend (access R/W1TC)
  [2] NAVSS512J7AM_VIRTSS_DATA_CBASS_AC_SLV2_M2M_BRIDGE_NAVSS512J7AM_VIRTSS_DATA_CBASS_AC_SLV2_M2M_BRIDGE_SRC_EDC_CTRL_BUSECC_ENABLE_CLR — Interrupt Enable Clear Register for navss512j7am_virtss_data_cbass_ac_slv2_m2m_bridge_navss512j7am_virtss_data_cbass_ac_slv2_m2m_bridge_src_edc_ctrl_busecc_pend (access R/W1TC)
  [1] NAVSS512J7AM_VIRTSS_DATA_CBASS_AC_SLV1_M2M_BRIDGE_NAVSS512J7AM_VIRTSS_DATA_CBASS_AC_SLV1_M2M_BRIDGE_SRC_EDC_CTRL_BUSECC_ENABLE_CLR — Interrupt Enable Clear Register for navss512j7am_virtss_data_cbass_ac_slv1_m2m_bridge_navss512j7am_virtss_data_cbass_ac_slv1_m2m_bridge_src_edc_ctrl_busecc_pend (access R/W1TC)
  [0] NAVSS512J7AM_VIRTSS_DATA_CBASS_AC_SLV0_M2M_BRIDGE_NAVSS512J7AM_VIRTSS_DATA_CBASS_AC_SLV0_M2M_BRIDGE_SRC_EDC_CTRL_BUSECC_ENABLE_CLR — Interrupt Enable Clear Register for navss512j7am_virtss_data_cbass_ac_slv0_m2m_bridge_navss512j7am_virtss_data_cbass_ac_slv0_m2m_bridge_src_edc_ctrl_busecc_pend (access R/W1TC)
0x13C VIRTSS_ECCAGGR_CFG_REGS_ded_eoi_reg — EOI Register
  [0] EOI_WR — EOI Register (access R/W1TS)
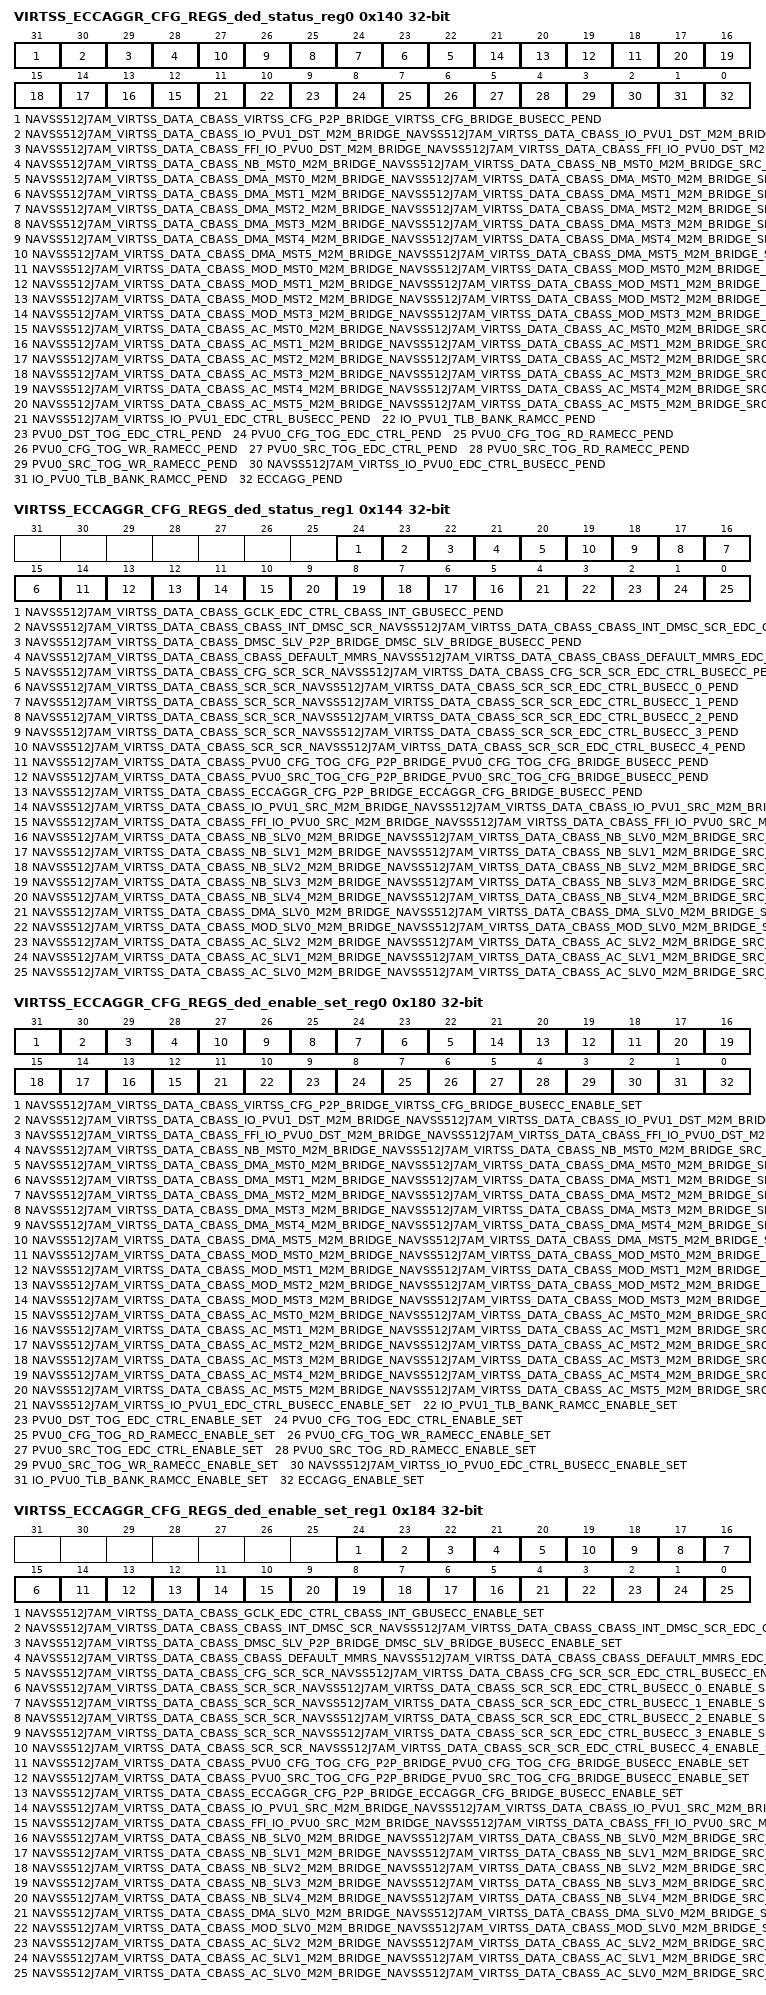
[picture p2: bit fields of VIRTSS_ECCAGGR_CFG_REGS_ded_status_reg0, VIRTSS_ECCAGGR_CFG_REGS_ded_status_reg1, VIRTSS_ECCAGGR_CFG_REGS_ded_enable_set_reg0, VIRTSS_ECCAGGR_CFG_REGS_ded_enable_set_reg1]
0x140 VIRTSS_ECCAGGR_CFG_REGS_ded_status_reg0 — Interrupt Status Register 0
  fields as VIRTSS_ECCAGGR_CFG_REGS_sec_status_reg0
0x144 VIRTSS_ECCAGGR_CFG_REGS_ded_status_reg1 — Interrupt Status Register 1
  fields as VIRTSS_ECCAGGR_CFG_REGS_sec_status_reg1
0x180 VIRTSS_ECCAGGR_CFG_REGS_ded_enable_set_reg0 — Interrupt Enable Set Register 0
  fields as VIRTSS_ECCAGGR_CFG_REGS_sec_enable_set_reg0
0x184 VIRTSS_ECCAGGR_CFG_REGS_ded_enable_set_reg1 — Interrupt Enable Set Register 1
  fields as VIRTSS_ECCAGGR_CFG_REGS_sec_enable_set_reg1
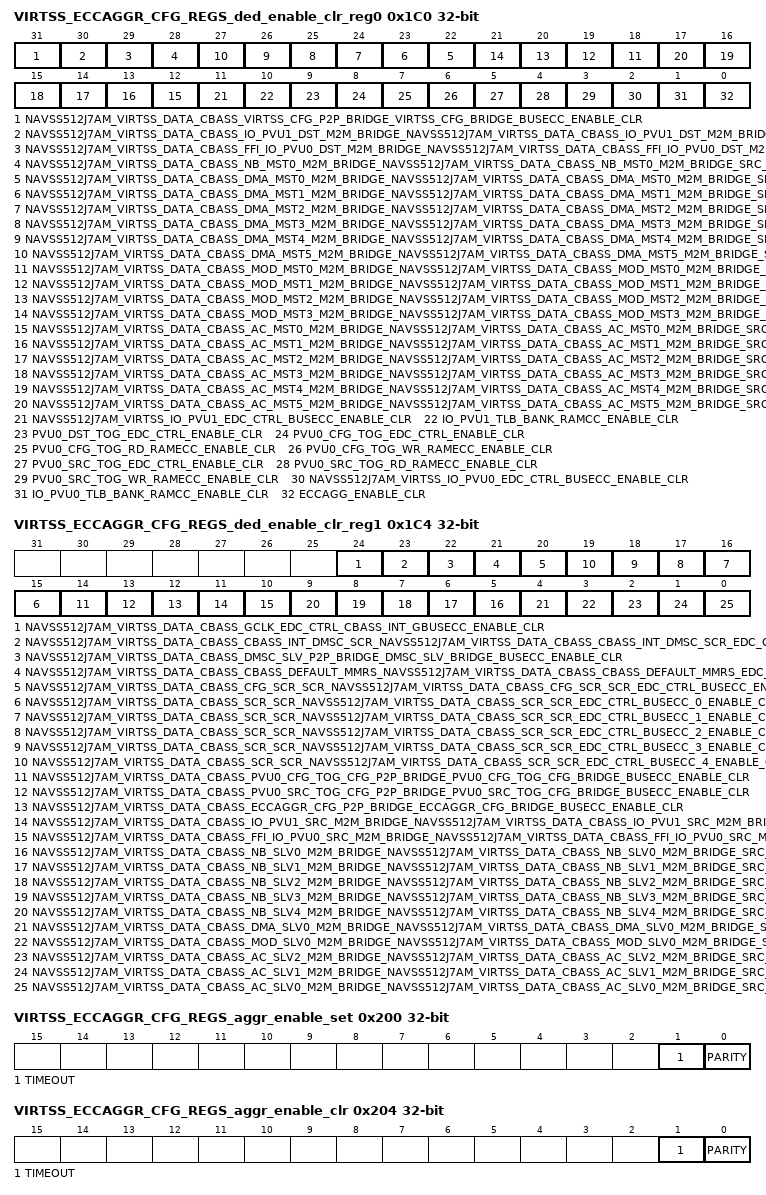
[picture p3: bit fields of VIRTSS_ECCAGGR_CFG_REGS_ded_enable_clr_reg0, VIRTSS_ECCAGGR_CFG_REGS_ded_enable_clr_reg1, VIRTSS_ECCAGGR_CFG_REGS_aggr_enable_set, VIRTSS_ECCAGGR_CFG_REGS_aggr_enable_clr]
0x1C0 VIRTSS_ECCAGGR_CFG_REGS_ded_enable_clr_reg0 — Interrupt Enable Clear Register 0
  fields as VIRTSS_ECCAGGR_CFG_REGS_sec_enable_clr_reg0
0x1C4 VIRTSS_ECCAGGR_CFG_REGS_ded_enable_clr_reg1 — Interrupt Enable Clear Register 1
  fields as VIRTSS_ECCAGGR_CFG_REGS_sec_enable_clr_reg1
0x200 VIRTSS_ECCAGGR_CFG_REGS_aggr_enable_set — AGGR interrupt enable set Register
  [1] TIMEOUT — interrupt enable set for svbus timeout errors (access R/W1TS)
  [0] PARITY — interrupt enable set for parity errors (access R/W1TS)
0x204 VIRTSS_ECCAGGR_CFG_REGS_aggr_enable_clr — AGGR interrupt enable clear Register
  [1] TIMEOUT — interrupt enable clear for svbus timeout errors (access R/W1TC)
  [0] PARITY — interrupt enable clear for parity errors (access R/W1TC)
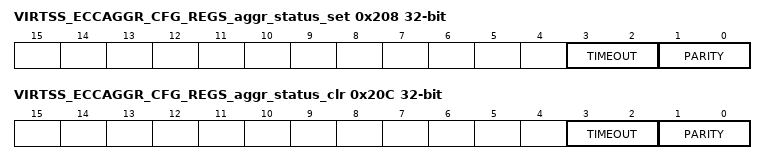
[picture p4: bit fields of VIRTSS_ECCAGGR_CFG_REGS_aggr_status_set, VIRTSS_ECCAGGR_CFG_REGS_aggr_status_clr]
0x208 VIRTSS_ECCAGGR_CFG_REGS_aggr_status_set — AGGR interrupt status set Register
  [3:2] TIMEOUT — interrupt status set for svbus timeout errors (access R/WI)
  [1:0] PARITY — interrupt status set for parity errors (access R/WI)
0x20C VIRTSS_ECCAGGR_CFG_REGS_aggr_status_clr — AGGR interrupt status clear Register
  [3:2] TIMEOUT — interrupt status clear for svbus timeout errors (access R/WD)
  [1:0] PARITY — interrupt status clear for parity errors (access R/WD)
